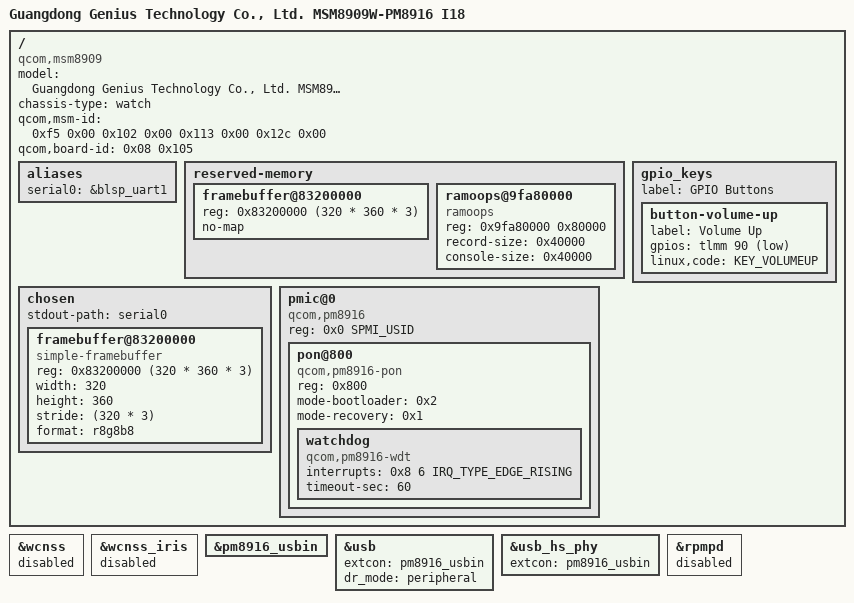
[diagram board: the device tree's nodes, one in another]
// SPDX-License-Identifier: GPL-2.0-only
/dts-v1/;

#include "qcom-msm8909.dtsi"
#include "../../../../arm64/boot/dts/qcom/pm8916.dtsi"
#include <dt-bindings/gpio/gpio.h>
#include <dt-bindings/input/input.h>
#include <dt-bindings/interrupt-controller/irq.h>
#include <dt-bindings/leds/common.h>
#include <dt-bindings/pinctrl/qcom,pmic-mpp.h>

/ {
	model = "Guangdong Genius Technology Co., Ltd. MSM8909W-PM8916 I18";
	compatible = "qcom,msm8909", "qcom,mtp", "qcom,msm8909-i18";
	chassis-type = "watch";
	qcom,msm-id = <0xf5 0x00 0x102 0x00 0x113 0x00 0x12c 0x00>;
	qcom,board-id = <0x08 0x105>;

	aliases {
		// mmc0 = &sdhc_1;
		serial0 = &blsp_uart1;
	};

	reserved-memory {
		#address-cells = <1>;
		#size-cells = <1>;
		ranges;

		framebuffer@83200000 {
            reg = <0x83200000 (320 * 360 * 3)>; /* 12MB reserved */
            no-map;
        };

		ramoops@9fa80000 {
			compatible = "ramoops";
			reg = <0x9fa80000 0x80000>; /* 512KB total size */
			record-size = <0x40000>;     /* 256KB for panic logs (0x9fa80000) */
			console-size = <0x40000>;    /* 256KB for console (0x9fac0000) */
		};
	};

	chosen {
        #address-cells = <1>;
        #size-cells = <1>;
        ranges;
		stdout-path = "serial0";
        
		framebuffer@83200000 {
			compatible = "simple-framebuffer";
			reg = <0x83200000 (320 * 360 * 3)>;

			width = <320>;
			height = <360>;
			stride = <(320 * 3)>;
			format = "r8g8b8";

			// power-domains = <&gcc MDSS_GDSC>;

			// clocks = <&gcc GCC_MDSS_AHB_CLK>,
			// 	 <&gcc GCC_MDSS_AXI_CLK>,
			// 	 <&gcc GCC_MDSS_VSYNC_CLK>,
			// 	 <&gcc GCC_MDSS_MDP_CLK>,
			// 	 <&gcc GCC_MDSS_BYTE0_CLK>,
			// 	 <&gcc GCC_MDSS_PCLK0_CLK>,
			// 	 <&gcc GCC_MDSS_ESC0_CLK>;
		};
	};

	gpio_keys {
		status = "okay";
		label = "GPIO Buttons";

		button-volume-up {
			label = "Volume Up";
			gpios = <&tlmm 90 GPIO_ACTIVE_LOW>;
			linux,code = <KEY_VOLUMEUP>;
		};
	};

	pmic@0 {
        compatible = "qcom,pm8916", "qcom,spmi-pmic";
        reg = <0x0 SPMI_USID>;
        #address-cells = <1>;
        #size-cells = <0>;

        pon@800 {
            compatible = "qcom,pm8916-pon";
            reg = <0x800>;
            mode-bootloader = <0x2>;
            mode-recovery = <0x1>;

            watchdog {
                compatible = "qcom,pm8916-wdt";
                interrupts = <0x8 6 IRQ_TYPE_EDGE_RISING>;
                timeout-sec = <60>;
            };
        };
    };
};

&wcnss { status = "disabled"; };
&wcnss_iris { status = "disabled"; };

&pm8916_usbin {
	status = "okay";
};

&usb {
	extcon = <&pm8916_usbin>;
	dr_mode = "peripheral";
	status = "okay";
};

&usb_hs_phy {
	extcon = <&pm8916_usbin>;
};

// fix hang after 0.5s
&rpmpd {
    status = "disabled";
};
